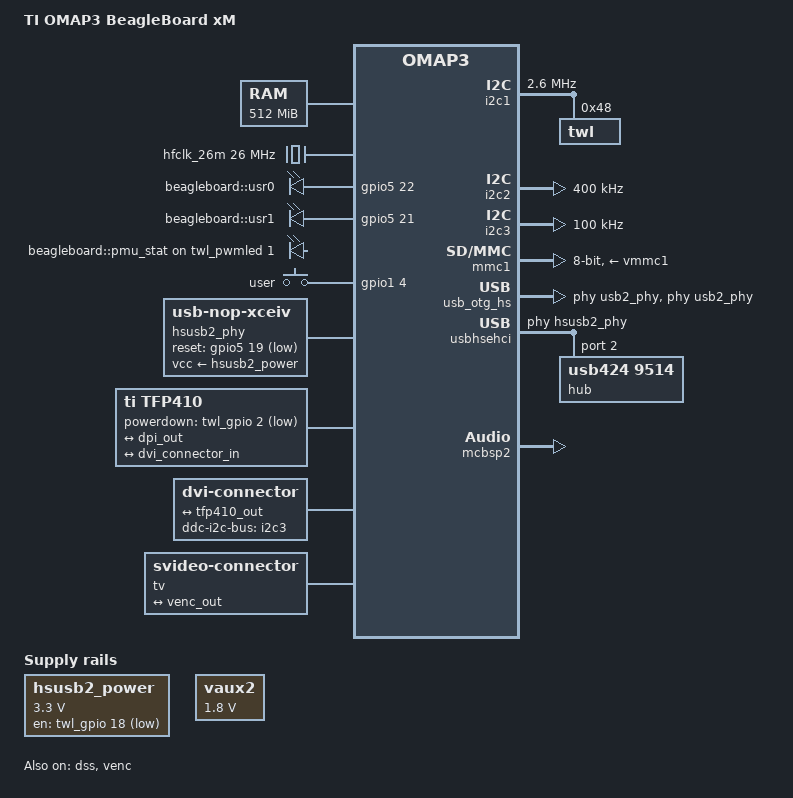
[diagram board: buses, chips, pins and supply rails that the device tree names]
/dts-v1/;
#include "omap36xx.dtsi"
/ {
	model = "TI OMAP3 BeagleBoard xM";
	compatible = "ti,omap3-beagle-xm", "ti,omap3630", "ti,omap3";
	cpus {
		cpu@0 {
			cpu0-supply = <&vcc>;
		};
	};
	memory@80000000 {
		device_type = "memory";
		reg = <0x80000000 0x20000000>;  
	};
	aliases {
		display0 = &dvi0;
		display1 = &tv0;
		ethernet = &ethernet;
	};
	hfclk_26m: oscillator {
		#clock-cells = <0>;
		compatible = "fixed-clock";
		clock-frequency = <26000000>;
	};
	led-controller-1 {
		compatible = "gpio-leds";
		led-1 {
			label = "beagleboard::usr0";
			gpios = <&gpio5 22 GPIO_ACTIVE_HIGH>;  
			linux,default-trigger = "heartbeat";
		};
		led-2 {
			label = "beagleboard::usr1";
			gpios = <&gpio5 21 GPIO_ACTIVE_HIGH>;  
			linux,default-trigger = "mmc0";
		};
	};
	led-controller-2 {
		compatible = "pwm-leds";
		led-3 {
			label = "beagleboard::pmu_stat";
			pwms = <&twl_pwmled 1 7812500>;
			max-brightness = <127>;
		};
	};
	sound {
		compatible = "ti,omap-twl4030";
		ti,model = "omap3beagle";
		ti,mcbsp = <&mcbsp2>;
	};
	gpio_keys {
		compatible = "gpio-keys";
		user {
			label = "user";
			gpios = <&gpio1 4 GPIO_ACTIVE_HIGH>;
			linux,code = <0x114>;
			wakeup-source;
		};
	};
	hsusb2_power: hsusb2_power_reg {
		compatible = "regulator-fixed";
		regulator-name = "hsusb2_vbus";
		regulator-min-microvolt = <3300000>;
		regulator-max-microvolt = <3300000>;
		gpio = <&twl_gpio 18 GPIO_ACTIVE_HIGH>;	 
		startup-delay-us = <70000>;
	};
	hsusb2_phy: hsusb2-phy-pins {
		compatible = "usb-nop-xceiv";
		reset-gpios = <&gpio5 19 GPIO_ACTIVE_LOW>;  
		vcc-supply = <&hsusb2_power>;
		#phy-cells = <0>;
	};
	tfp410: encoder0 {
		compatible = "ti,tfp410";
		powerdown-gpios = <&twl_gpio 2 GPIO_ACTIVE_LOW>;
		ports {
			#address-cells = <1>;
			#size-cells = <0>;
			port@0 {
				reg = <0>;
				tfp410_in: endpoint {
					remote-endpoint = <&dpi_out>;
				};
			};
			port@1 {
				reg = <1>;
				tfp410_out: endpoint {
					remote-endpoint = <&dvi_connector_in>;
				};
			};
		};
	};
	dvi0: connector0 {
		compatible = "dvi-connector";
		label = "dvi";
		digital;
		ddc-i2c-bus = <&i2c3>;
		port {
			dvi_connector_in: endpoint {
				remote-endpoint = <&tfp410_out>;
			};
		};
	};
	tv0: connector1 {
		compatible = "svideo-connector";
		label = "tv";
		port {
			tv_connector_in: endpoint {
				remote-endpoint = <&venc_out>;
			};
		};
	};
	etb@5401b000 {
		compatible = "arm,coresight-etb10", "arm,primecell";
		reg = <0x5401b000 0x1000>;
		clocks = <&emu_src_ck>;
		clock-names = "apb_pclk";
		in-ports {
			port {
				etb_in: endpoint {
					remote-endpoint = <&etm_out>;
				};
			};
		};
	};
	etm@54010000 {
		compatible = "arm,coresight-etm3x", "arm,primecell";
		reg = <0x54010000 0x1000>;
		clocks = <&emu_src_ck>;
		clock-names = "apb_pclk";
		out-ports {
			port {
				etm_out: endpoint {
					remote-endpoint = <&etb_in>;
				};
			};
		};
	};
};
&omap3_pmx_wkup {
	gpio1_pins: gpio1-pins {
		pinctrl-single,pins = <
			OMAP3_WKUP_IOPAD(0x2a0e, PIN_INPUT | PIN_OFF_WAKEUPENABLE | MUX_MODE4)  
		>;
	};
	dss_dpi_pins2: dss-dpi1-pins {
		pinctrl-single,pins = <
			OMAP3_WKUP_IOPAD(0x2a0a, PIN_OUTPUT | MUX_MODE3)    
			OMAP3_WKUP_IOPAD(0x2a0c, PIN_OUTPUT | MUX_MODE3)    
			OMAP3_WKUP_IOPAD(0x2a10, PIN_OUTPUT | MUX_MODE3)    
			OMAP3_WKUP_IOPAD(0x2a12, PIN_OUTPUT | MUX_MODE3)    
			OMAP3_WKUP_IOPAD(0x2a14, PIN_OUTPUT | MUX_MODE3)    
			OMAP3_WKUP_IOPAD(0x2a16, PIN_OUTPUT | MUX_MODE3)    
		>;
	};
};
&omap3_pmx_core {
	pinctrl-names = "default";
	pinctrl-0 = <
			&hsusb2_pins
	>;
	uart3_pins: uart3-pins {
		pinctrl-single,pins = <
			OMAP3_CORE1_IOPAD(0x219e, PIN_INPUT | MUX_MODE0)	 
			OMAP3_CORE1_IOPAD(0x21a0, PIN_OUTPUT | MUX_MODE0)	 
		>;
	};
	hsusb2_pins: hsusb2-pins {
		pinctrl-single,pins = <
			OMAP3_CORE1_IOPAD(0x21d4, PIN_INPUT_PULLDOWN | MUX_MODE3)	 
			OMAP3_CORE1_IOPAD(0x21d6, PIN_INPUT_PULLDOWN | MUX_MODE3)	 
			OMAP3_CORE1_IOPAD(0x21d8, PIN_INPUT_PULLDOWN | MUX_MODE3)	 
			OMAP3_CORE1_IOPAD(0x21da, PIN_INPUT_PULLDOWN | MUX_MODE3)	 
			OMAP3_CORE1_IOPAD(0x21dc, PIN_INPUT_PULLDOWN | MUX_MODE3)	 
			OMAP3_CORE1_IOPAD(0x21de, PIN_INPUT_PULLDOWN | MUX_MODE3)	 
		>;
	};
	dss_dpi_pins1: dss-dpi2-pins {
		pinctrl-single,pins = <
			OMAP3_CORE1_IOPAD(0x20d4, PIN_OUTPUT | MUX_MODE0)    
			OMAP3_CORE1_IOPAD(0x20d6, PIN_OUTPUT | MUX_MODE0)    
			OMAP3_CORE1_IOPAD(0x20d8, PIN_OUTPUT | MUX_MODE0)    
			OMAP3_CORE1_IOPAD(0x20da, PIN_OUTPUT | MUX_MODE0)    
			OMAP3_CORE1_IOPAD(0x20e8, PIN_OUTPUT | MUX_MODE0)    
			OMAP3_CORE1_IOPAD(0x20ea, PIN_OUTPUT | MUX_MODE0)    
			OMAP3_CORE1_IOPAD(0x20ec, PIN_OUTPUT | MUX_MODE0)    
			OMAP3_CORE1_IOPAD(0x20ee, PIN_OUTPUT | MUX_MODE0)    
			OMAP3_CORE1_IOPAD(0x20f0, PIN_OUTPUT | MUX_MODE0)    
			OMAP3_CORE1_IOPAD(0x20f2, PIN_OUTPUT | MUX_MODE0)    
			OMAP3_CORE1_IOPAD(0x20f4, PIN_OUTPUT | MUX_MODE0)    
			OMAP3_CORE1_IOPAD(0x20f6, PIN_OUTPUT | MUX_MODE0)    
			OMAP3_CORE1_IOPAD(0x20f8, PIN_OUTPUT | MUX_MODE0)    
			OMAP3_CORE1_IOPAD(0x20fa, PIN_OUTPUT | MUX_MODE0)    
			OMAP3_CORE1_IOPAD(0x20fc, PIN_OUTPUT | MUX_MODE0)    
			OMAP3_CORE1_IOPAD(0x20fe, PIN_OUTPUT | MUX_MODE0)    
			OMAP3_CORE1_IOPAD(0x2100, PIN_OUTPUT | MUX_MODE3)    
			OMAP3_CORE1_IOPAD(0x2102, PIN_OUTPUT | MUX_MODE3)    
			OMAP3_CORE1_IOPAD(0x2104, PIN_OUTPUT | MUX_MODE3)    
			OMAP3_CORE1_IOPAD(0x2106, PIN_OUTPUT | MUX_MODE3)    
			OMAP3_CORE1_IOPAD(0x2108, PIN_OUTPUT | MUX_MODE3)    
			OMAP3_CORE1_IOPAD(0x210a, PIN_OUTPUT | MUX_MODE3)    
		>;
	};
};
&omap3_pmx_core2 {
	pinctrl-names = "default";
	pinctrl-0 = <
			&hsusb2_2_pins
	>;
	hsusb2_2_pins: hsusb2-2-pins {
		pinctrl-single,pins = <
			OMAP3630_CORE2_IOPAD(0x25f0, PIN_OUTPUT | MUX_MODE3)		 
			OMAP3630_CORE2_IOPAD(0x25f2, PIN_OUTPUT | MUX_MODE3)		 
			OMAP3630_CORE2_IOPAD(0x25f4, PIN_INPUT_PULLDOWN | MUX_MODE3)	 
			OMAP3630_CORE2_IOPAD(0x25f6, PIN_INPUT_PULLDOWN | MUX_MODE3)	 
			OMAP3630_CORE2_IOPAD(0x25f8, PIN_INPUT_PULLDOWN | MUX_MODE3)	 
			OMAP3630_CORE2_IOPAD(0x25fa, PIN_INPUT_PULLDOWN | MUX_MODE3)	 
		>;
	};
};
&i2c1 {
	clock-frequency = <2600000>;
	twl: twl@48 {
		reg = <0x48>;
		interrupts = <7>;  
		interrupt-parent = <&intc>;
		clocks = <&hfclk_26m>;
		clock-names = "fck";
		twl_audio: audio {
			compatible = "ti,twl4030-audio";
			codec {
			};
		};
		twl_power: power {
			compatible = "ti,twl4030-power-beagleboard-xm", "ti,twl4030-power-idle-osc-off";
			ti,use_poweroff;
		};
	};
};
#include "twl4030.dtsi"
#include "twl4030_omap3.dtsi"
&i2c2 {
	clock-frequency = <400000>;
};
&i2c3 {
	clock-frequency = <100000>;
};
&mmc1 {
	vmmc-supply = <&vmmc1>;
	vqmmc-supply = <&vsim>;
	bus-width = <8>;
};
&mmc2 {
	status = "disabled";
};
&mmc3 {
	status = "disabled";
};
&twl_gpio {
	ti,use-leds;
	ti,pullups = <0x000002>;
	ti,pulldowns = <0x03a1c4>;
};
&usb_otg_hs {
	interface-type = <0>;
	usb-phy = <&usb2_phy>;
	phys = <&usb2_phy>;
	phy-names = "usb2-phy";
	mode = <3>;
	power = <50>;
};
&uart3 {
	interrupts-extended = <&intc 74 &omap3_pmx_core OMAP3_UART3_RX>;
	pinctrl-names = "default";
	pinctrl-0 = <&uart3_pins>;
};
&gpio1 {
	pinctrl-names = "default";
	pinctrl-0 = <&gpio1_pins>;
};
&usbhshost {
	port2-mode = "ehci-phy";
};
&usbhsehci {
	phys = <0 &hsusb2_phy>;
	#address-cells = <1>;
	#size-cells = <0>;
	hub@2 {
		compatible = "usb424,9514";
		reg = <2>;
		#address-cells = <1>;
		#size-cells = <0>;
		ethernet: ethernet@1 {
			compatible = "usb424,ec00";
			reg = <1>;
		};
	};
};
&vaux2 {
	regulator-name = "usb_1v8";
	regulator-min-microvolt = <1800000>;
	regulator-max-microvolt = <1800000>;
	regulator-always-on;
};
&mcbsp2 {
	status = "okay";
};
&dss {
	status = "okay";
	pinctrl-names = "default";
	pinctrl-0 = <
		&dss_dpi_pins1
		&dss_dpi_pins2
	>;
	port {
		dpi_out: endpoint {
			remote-endpoint = <&tfp410_in>;
			data-lines = <24>;
		};
	};
};
&venc {
	status = "okay";
	vdda-supply = <&vdac>;
	port {
		venc_out: endpoint {
			remote-endpoint = <&tv_connector_in>;
			ti,channels = <2>;
		};
	};
};
